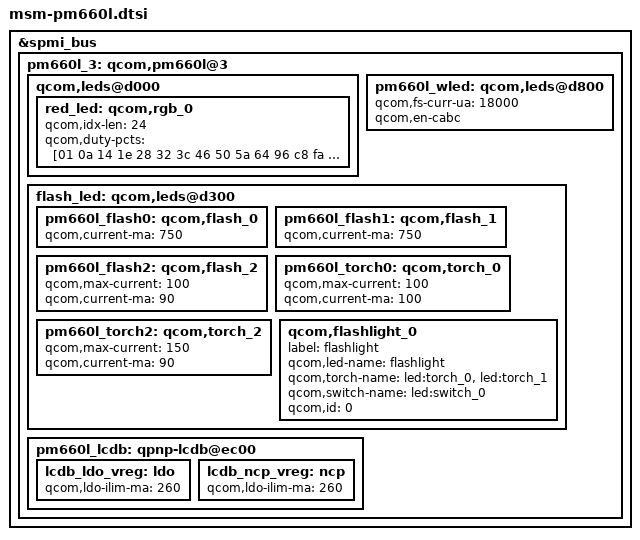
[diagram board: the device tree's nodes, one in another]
/* Copyright (c) 2016-2017, The Linux Foundation. All rights reserved.
 * Copyright (C) 2018 XiaoMi, Inc.
 *
 * This program is free software; you can redistribute it and/or modify
 * it under the terms of the GNU General Public License version 2 and
 * only version 2 as published by the Free Software Foundation.
 *
 * This program is distributed in the hope that it will be useful,
 * but WITHOUT ANY WARRANTY; without even the implied warranty of
 * MERCHANTABILITY or FITNESS FOR A PARTICULAR PURPOSE.  See the
 * GNU General Public License for more details.
*/

&spmi_bus {
	pm660l_3: qcom,pm660l@3 {
		qcom,leds@d000 {
			red_led: qcom,rgb_0 {
				qcom,idx-len = <24>;
				qcom,duty-pcts =
					[01 0a 14 1e 28 32 3c 46 50 5a
					 64 96 c8 fa
					96 5a 50 46 3c 32 28 1e 14 0a];
			};
		};
		pm660l_wled: qcom,leds@d800 {
			qcom,fs-curr-ua = <18000>;
			qcom,en-cabc;
			/delete-property/qcom,auto-calibration-enable;
		};
		flash_led: qcom,leds@d300 {
			pm660l_flash0: qcom,flash_0 {
				qcom,current-ma = <750>;
			};
			pm660l_flash1: qcom,flash_1 {
				qcom,current-ma = <750>;
			};
			pm660l_flash2: qcom,flash_2 {
				qcom,max-current = <100>;
				qcom,current-ma = <90>;
			};
			pm660l_torch0: qcom,torch_0 {
 				qcom,max-current = <100>;
				qcom,current-ma = <100>;
			};
			pm660l_torch2: qcom,torch_2 {
 				qcom,max-current = <150>;
				qcom,current-ma = <90>;
			};

			qcom,flashlight_0 {
				label = "flashlight";
				qcom,led-name = "flashlight";
				qcom,torch-name = "led:torch_0", "led:torch_1";
				qcom,switch-name = "led:switch_0";
				qcom,id = <0>;
			};
		};
		pm660l_lcdb: qpnp-lcdb@ec00 {
			lcdb_ldo_vreg: ldo {
				qcom,ldo-ilim-ma = <260>;
			};
			lcdb_ncp_vreg: ncp {
				qcom,ldo-ilim-ma = <260>;
			};
		};
	};
};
